# R7FA0L107 register map
Vendor: Renesas Electronics Corporation; Series: RA0; File version: 1.10.01
CPU: CM23 r1p0, little endian, no MPU, no FPU, VTOR, 2 interrupt priority bits, 64 interrupts
Registers are 16-bit, read-write, reset 0x0 unless marked. A register's access mark holds for its fields unless they carry their own. Offsets are from the block's base; [hi:lo] are bit positions; {n}, {i} and the like mark numbered series.

## PORT2 — Port 2 Control
Base 0x400A0040
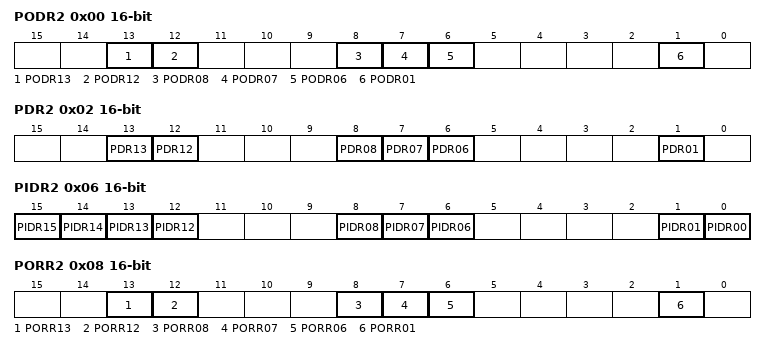
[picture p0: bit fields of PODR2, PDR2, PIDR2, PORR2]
0x00 PODR2 — Port 2 Output Data Register
  [all] fields
    0=Low output; 1=High output
  [13] PODR13 — P213 Output Data
  [12] PODR12 — P212 Output Data
  [8] PODR08 — P208 Output Data
  [7] PODR07 — P207 Output Data
  [6] PODR06 — P206 Output Data
  [1] PODR01 — P201 Output Data
0x02 PDR2 — Port 2 Direction Register
  [all] fields
    0=Output 0; 1=Output 1
  [13] PDR13 — P213 Direction
  [12] PDR12 — P212 Direction
  [8] PDR08 — P208 Direction
  [7] PDR07 — P207 Direction
  [6] PDR06 — P206 Direction
  [1] PDR01 — P201 Direction
0x06 PIDR2 ro (reset mask 0xE3C) — Port 2 State Register
  [all] fields
    0=Low level; 1=High level
  [n] PIDR{n} (n=12..15) — P{n+200} State
  [8] PIDR08 — P208 State
  [7] PIDR07 — P207 State
  [6] PIDR06 — P206 State
  [1] PIDR01 — P201 State
  [0] PIDR00 — P200 State
0x08 PORR2 wo — Port 2 Output Reset Register
  [all] fields
    0=No effect on output; 1=Low output
  [13] PORR13 — P213 Output Reset
  [12] PORR12 — P212 Output Reset
  [8] PORR08 — P208 Output Reset
  [7] PORR07 — P207 Output Reset
  [6] PORR06 — P206 Output Reset
  [1] PORR01 — P201 Output Reset
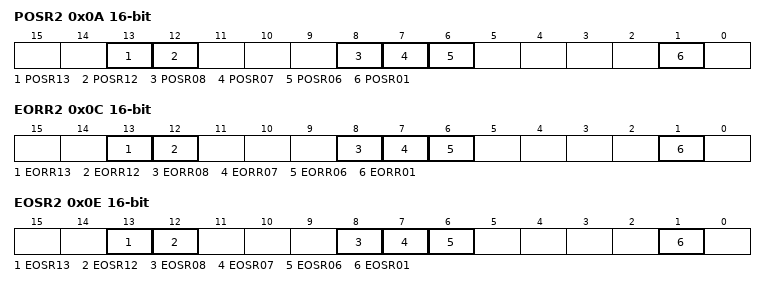
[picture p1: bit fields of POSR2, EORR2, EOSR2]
0x0A POSR2 wo — Port 2 Output Set Register
  [all] fields
    0=No effect on output; 1=High output
  [13] POSR13 — P213 Output Set
  [12] POSR12 — P212 Output Set
  [8] POSR08 — P208 Output Set
  [7] POSR07 — P207 Output Set
  [6] POSR06 — P206 Output Set
  [1] POSR01 — P201 Output Set
0x0C EORR2 — Port 2 Event Output Reset Register
  [all] fields
    0=No effect on output; 1=Low output
  [13] EORR13 — P213 Event Output Reset
  [12] EORR12 — P212 Event Output Reset
  [8] EORR08 — P208 Event Output Reset
  [7] EORR07 — P207 Event Output Reset
  [6] EORR06 — P206 Event Output Reset
  [1] EORR01 — P201 Event Output Reset
0x0E EOSR2 — Port 2 Event Output Set Register
  [all] fields
    0=No effect on output; 1=High output
  [13] EOSR13 — P213 Event Output Set
  [12] EOSR12 — P212 Event Output Set
  [8] EOSR08 — P208 Event Output Set
  [7] EOSR07 — P207 Event Output Set
  [6] EOSR06 — P206 Event Output Set
  [1] EOSR01 — P201 Event Output Set

## PORT3 — Port 3 Control
Base 0x400A0060
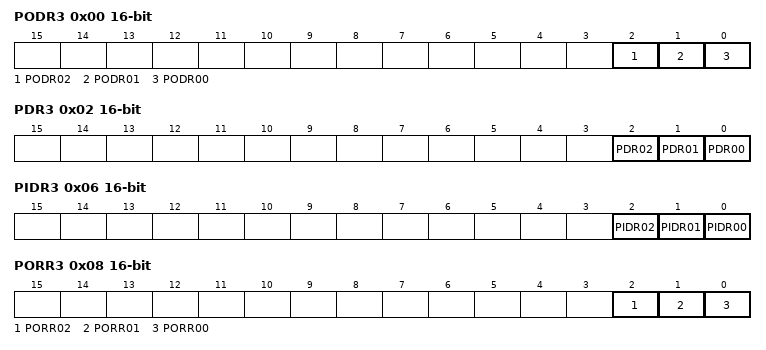
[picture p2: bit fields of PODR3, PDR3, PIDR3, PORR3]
0x00 PODR3 — Port 3 Output Data Register
  [all] fields
    0=Low output; 1=High output
  [2] PODR02 — P302 Output Data
  [1] PODR01 — P301 Output Data
  [0] PODR00 — P300 Output Data
0x02 PDR3 — Port 3 Direction Register
  [all] fields
    0=Output 0; 1=Output 1
  [2] PDR02 — P302 Direction
  [1] PDR01 — P301 Direction
  [0] PDR00 — P300 Direction
0x06 PIDR3 ro (reset mask 0xFFF8) — Port 3 State Register
  [all] fields
    0=Low level; 1=High level
  [2] PIDR02 — P302 State
  [1] PIDR01 — P301 State
  [0] PIDR00 — P300 State
0x08 PORR3 wo — Port 3 Output Reset Register
  [all] fields
    0=No effect on output; 1=Low output
  [2] PORR02 — P302 Output Reset
  [1] PORR01 — P301 Output Reset
  [0] PORR00 — P300 Output Reset
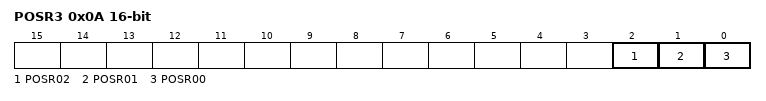
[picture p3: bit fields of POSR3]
0x0A POSR3 wo — Port 3 Output Set Register
  [all] fields
    0=No effect on output; 1=High output
  [2] POSR02 — P302 Output Set
  [1] POSR01 — P301 Output Set
  [0] POSR00 — P300 Output Set

## PORT4 — Port 4 Control
Base 0x400A0080
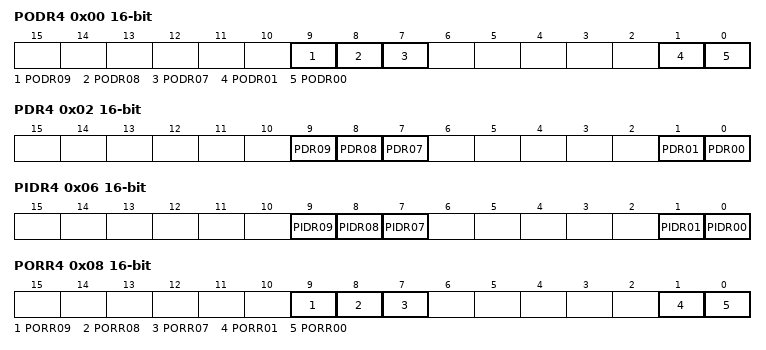
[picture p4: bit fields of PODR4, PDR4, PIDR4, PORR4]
0x00 PODR4 — Port 4 Output Data Register
  [all] fields
    0=Low output; 1=High output
  [9] PODR09 — P409 Output Data
  [8] PODR08 — P408 Output Data
  [7] PODR07 — P407 Output Data
  [1] PODR01 — P401 Output Data
  [0] PODR00 — P400 Output Data
0x02 PDR4 — Port 4 Direction Register
  [all] fields
    0=Output 0; 1=Output 1
  [9] PDR09 — P409 Direction
  [8] PDR08 — P408 Direction
  [7] PDR07 — P407 Direction
  [1] PDR01 — P401 Direction
  [0] PDR00 — P400 Direction
0x06 PIDR4 ro (reset mask 0xFC7C) — Port 4 State Register
  [all] fields
    0=Low level; 1=High level
  [9] PIDR09 — P409 State
  [8] PIDR08 — P408 State
  [7] PIDR07 — P407 State
  [1] PIDR01 — P401 State
  [0] PIDR00 — P400 State
0x08 PORR4 wo — Port 4 Output Reset Register
  [all] fields
    0=No effect on output; 1=Low output
  [9] PORR09 — P409 Output Reset
  [8] PORR08 — P408 Output Reset
  [7] PORR07 — P407 Output Reset
  [1] PORR01 — P401 Output Reset
  [0] PORR00 — P400 Output Reset
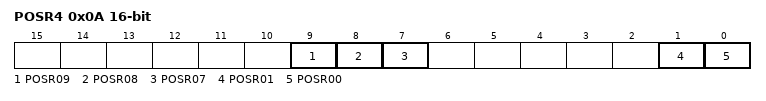
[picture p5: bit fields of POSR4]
0x0A POSR4 wo — Port 4 Output Set Register
  [all] fields
    0=No effect on output; 1=High output
  [9] POSR09 — P409 Output Set
  [8] POSR08 — P408 Output Set
  [7] POSR07 — P407 Output Set
  [1] POSR01 — P401 Output Set
  [0] POSR00 — P400 Output Set

## PORT5 — Port 5 Control
Base 0x400A00A0
0x00 PODR5 — Port 5 Output Data Register
  [0] PODR00 — P300 Output Data
    0=Low output; 1=High output
0x02 PDR5 — Port 5 Direction Register
  [0] PDR00 — P300 Direction
    0=Output 0; 1=Output 1
0x06 PIDR5 ro (reset mask 0xFFFE) — Port 5 State Register
  [0] PIDR00 — P300 State
    0=Low level; 1=High level
0x08 PORR5 wo — Port 5 Output Reset Register
  [0] PORR00 — P300 Output Reset
    0=No effect on output; 1=Low output
0x0A POSR5 wo — Port 5 Output Set Register
  [0] POSR00 — P300 Output Set
    0=No effect on output; 1=High output

## PORT9 — Port 9 Control
Base 0x400A0120
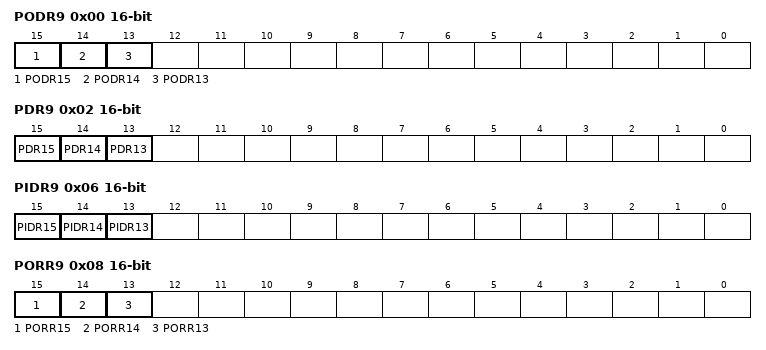
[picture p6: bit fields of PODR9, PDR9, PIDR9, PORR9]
0x00 PODR9 — Port 9 Output Data Register
  [all] fields
    0=Low output; 1=High output
  [15] PODR15 — P915 Output Data
  [14] PODR14 — P914 Output Data
  [13] PODR13 — P913 Output Data
0x02 PDR9 — Port 9 Direction Register
  [all] fields
    0=Output 0; 1=Output 1
  [15] PDR15 — P915 Direction
  [14] PDR14 — P914 Direction
  [13] PDR13 — P913 Direction
0x06 PIDR9 ro (reset mask 0x1FFF) — Port 9 State Register
  [all] fields
    0=Low level; 1=High level
  [15] PIDR15 — P915 State
  [14] PIDR14 — P914 State
  [13] PIDR13 — P913 State
0x08 PORR9 wo — Port 9 Output Reset Register
  [all] fields
    0=No effect on output; 1=Low output
  [15] PORR15 — P915 Output Reset
  [14] PORR14 — P914 Output Reset
  [13] PORR13 — P913 Output Reset
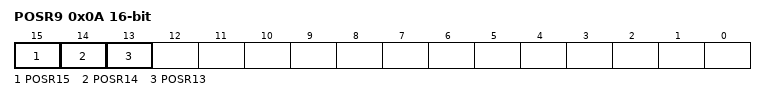
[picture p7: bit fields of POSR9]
0x0A POSR9 wo — Port 9 Output Set Register
  [all] fields
    0=No effect on output; 1=High output
  [15] POSR15 — P915 Output Set
  [14] POSR14 — P914 Output Set
  [13] POSR13 — P913 Output Set

## PCLBUZ — Clock Output/Buzzer Output Controller
Base 0x400A3B00
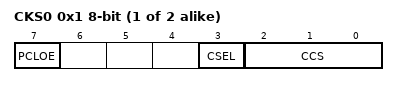
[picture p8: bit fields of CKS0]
{0x1+i} CKS{i} (i=0..1) 8-bit — Clock Out Control Register {i}
  [7] PCLOE — Clock Out Enable
    0=Disables clock out; 1=Enables clock out
  [3] CSEL — Clock Out Select
    0=FMAIN; 1=FSUB
  [2:0] CCS — Clock Out Divide Select
    0=Value after reset FMAIN (When CKSn.CSEL = 0) FSUB (When CKSn.CSEL = 1); 1=FMAIN × 1/2 (When CKSn.CSEL = 0) FSUB × 1/2 (When CKSn.CSEL = 1); 2=FMAIN × 1/22 (When CKSn.CSEL = 0) FSUB × 1/22 (When CKSn.CSEL = 1); 3=FMAIN × 1/23 (When CKSn.CSEL = 0) FSUB × 1/23 (When CKSn.CSEL = 1); 4=FMAIN × 1/24 (When CKSn.CSEL = 0) FSUB × 1/24 (When CKSn.CSEL = 1); 5=FMAIN × 1/211 (When CKSn.CSEL = 0) FSUB × 1/25 (When CKSn.CSEL = 1); 6=FMAIN 1/212 (When CKSn.CSEL = 0) FSUB × 1/26 (When CKSn.CSEL = 1); 7=FMAIN × 1/213 (When CKSn.CSEL = 0) FSUB × 1/27 (When CKSn.CSEL = 1)

## TRNG — True Random Number Generator
Base 0x400D1000
0x00 TRNGSDR 8-bit ro — TRNG Seed Data Register
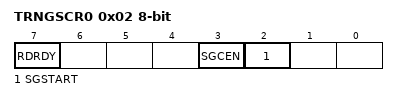
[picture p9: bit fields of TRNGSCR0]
0x02 TRNGSCR0 8-bit — TRNG Seed Command Register 0
  [7] RDRDY ro — Read Ready
  [3] SGCEN — Seed Generation Circuit Enable
    0=Seed generation circuit is disabled; 1=Seed generation circuit is enabled
  [2] SGSTART wo — Seed Generation Start
    0=No effect; 1=Start to generate the seed data
0x03 TRNGSCR1 8-bit — TRNG Seed Command Register 1
  [0] INTEN — TRNG Interrupt Enable
    0=TRNG interrupt is disabled; 1=TRNG interrupt is enabled
